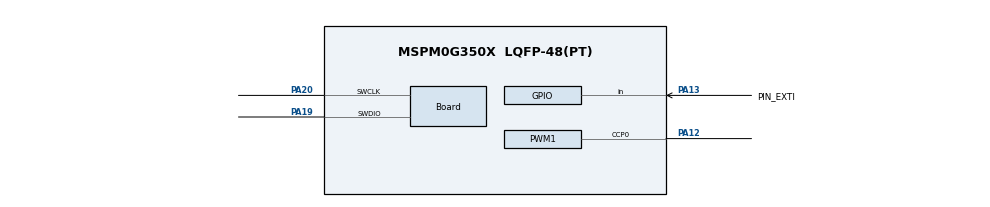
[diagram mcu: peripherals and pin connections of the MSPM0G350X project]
/**
 * @cliArgs --device "MSPM0G350X" --package "LQFP-48(PT)" --part "Default" --product "mspm0_sdk@2.01.00.03"
 * @versions {"tool":"1.20.0+3587"}
 */

/**
 * Import the modules used in this configuration.
 */
const GPIO          = scripting.addModule("/ti/driverlib/GPIO", {}, false);
const GPIO1         = GPIO.addInstance();
const GPIO2         = GPIO.addInstance();
const PWM           = scripting.addModule("/ti/driverlib/PWM", {}, false);
const PWM1          = PWM.addInstance();
const SYSCTL        = scripting.addModule("/ti/driverlib/SYSCTL");
const ProjectConfig = scripting.addModule("/ti/project_config/ProjectConfig");

/**
 * Write custom configuration values to the imported modules.
 */
GPIO1.$name                          = "GPIO_EXTI";
GPIO1.associatedPins[0].$name        = "PIN_EXTI";
GPIO1.associatedPins[0].direction    = "INPUT";
GPIO1.associatedPins[0].assignedPort = "PORTA";
GPIO1.associatedPins[0].assignedPin  = "13";
GPIO1.associatedPins[0].interruptEn  = true;
GPIO1.associatedPins[0].polarity     = "RISE";
GPIO1.associatedPins[0].pin.$assign  = "PA13";

const Board                       = scripting.addModule("/ti/driverlib/Board", {}, false);
Board.peripheral.$assign          = "DEBUGSS";
Board.peripheral.swclkPin.$assign = "PA20";
Board.peripheral.swdioPin.$assign = "PA19";

GPIO2.$name                          = "GPIO_LED";
GPIO2.associatedPins[0].$name        = "PIN_D2";
GPIO2.associatedPins[0].assignedPort = "PORTA";
GPIO2.associatedPins[0].assignedPin  = "14";

PWM1.$name                              = "PWM_TRIG";
PWM1.timerStartTimer                    = true;
PWM1.pwmMode                            = "EDGE_ALIGN_UP";
PWM1.ccIndex                            = [0];
PWM1.timerCount                         = 32000;
PWM1.clockPrescale                      = 100;
PWM1.peripheral.$assign                 = "TIMG0";
PWM1.peripheral.ccp0Pin.$assign         = "PA12";
PWM1.PWM_CHANNEL_0.$name                = "ti_driverlib_pwm_PWMTimerCC0";
PWM1.PWM_CHANNEL_0.dutyCycle            = 50;
PWM1.ccp0PinConfig.$name                = "ti_driverlib_gpio_GPIOPinGeneric0";
PWM1.ccp0PinConfig.direction            = scripting.forceWrite("OUTPUT");
PWM1.ccp0PinConfig.hideOutputInversion  = scripting.forceWrite(false);
PWM1.ccp0PinConfig.onlyInternalResistor = scripting.forceWrite(false);
PWM1.ccp0PinConfig.passedPeripheralType = scripting.forceWrite("Digital");

SYSCTL.forceDefaultClkConfig = true;
SYSCTL.peripheral.$assign    = "SYSCTL";

ProjectConfig.deviceSpin = "MSPM0G3507";

/**
 * Pinmux solution for unlocked pins/peripherals. This ensures that minor changes to the automatic solver in a future
 * version of the tool will not impact the pinmux you originally saw.  These lines can be completely deleted in order to
 * re-solve from scratch.
 */
GPIO2.associatedPins[0].pin.$suggestSolution = "PA14";
